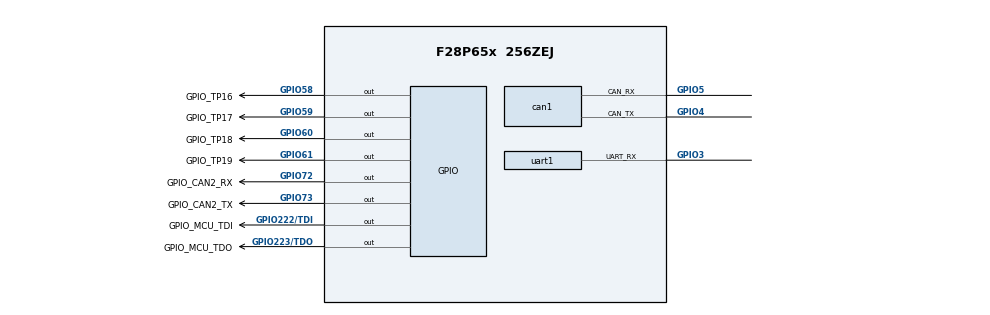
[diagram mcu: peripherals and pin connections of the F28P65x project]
/**
 * @cliArgs --device "F28P65x" --part "F28P65x_256ZEJ" --package "256ZEJ" --context "CPU1" --product "C2000WARE@6.00.01.00"
 * @versions {"tool":"1.26.0+4407"}
 */

/**
 * Import the modules used in this configuration.
 */
const adc       = scripting.addModule("/driverlib/adc.js", {}, false);
const adc1      = adc.addInstance();
const can       = scripting.addModule("/driverlib/can.js", {}, false);
const can1      = can.addInstance();
const gpio      = scripting.addModule("/driverlib/gpio.js", {}, false);
const gpio1     = gpio.addInstance();
const gpio2     = gpio.addInstance();
const gpio3     = gpio.addInstance();
const gpio4     = gpio.addInstance();
const gpio5     = gpio.addInstance();
const gpio6     = gpio.addInstance();
const gpio7     = gpio.addInstance();
const gpio8     = gpio.addInstance();
const uart      = scripting.addModule("/driverlib/uart.js", {}, false);
const uart1     = uart.addInstance();
const FREERTOS  = scripting.addModule("/kernel/freertos_tool/FREERTOS", {}, false);
const FREERTOS1 = FREERTOS.addInstance();

/**
 * Write custom configuration values to the imported modules.
 */
adc1.$name             = "myADC0";
adc1.adcClockPrescaler = "ADC_CLK_DIV_4_0";

const analog  = scripting.addModule("/driverlib/analog.js", {}, false);
const analog1 = analog.addInstance({}, false);
analog1.$name = "myANALOGPinMux0";
adc1.analog   = analog1;

can1.$name                 = "CAN1";
can1.can.can_rxPin.$assign = "GPIO5";
can1.can.can_txPin.$assign = "GPIO4";

gpio1.$name           = "GPIO_TP16";
gpio1.direction       = "GPIO_DIR_MODE_OUT";
gpio1.gpioPin.$assign = "GPIO58";

gpio2.$name           = "GPIO_TP17";
gpio2.direction       = "GPIO_DIR_MODE_OUT";
gpio2.gpioPin.$assign = "GPIO59";

gpio3.$name           = "GPIO_TP18";
gpio3.direction       = "GPIO_DIR_MODE_OUT";
gpio3.gpioPin.$assign = "GPIO60";

gpio4.$name           = "GPIO_TP19";
gpio4.direction       = "GPIO_DIR_MODE_OUT";
gpio4.gpioPin.$assign = "GPIO61";

gpio5.$name           = "GPIO_CAN2_RX";
gpio5.gpioPin.$assign = "GPIO72";

gpio6.$name           = "GPIO_CAN2_TX";
gpio6.direction       = "GPIO_DIR_MODE_OUT";
gpio6.gpioPin.$assign = "GPIO73";

gpio7.$name           = "GPIO_MCU_TDI";
gpio7.gpioPin.$assign = "GPIO222/TDI";

gpio8.$name           = "GPIO_MCU_TDO";
gpio8.direction       = "GPIO_DIR_MODE_OUT";
gpio8.gpioPin.$assign = "GPIO223/TDO";

uart1.$name                   = "UART";
uart1.uart.uart_rxPin.$assign = "GPIO3";
uart1.txQual.$name            = "myGPIOQUAL0";
uart1.rxQual.$name            = "myGPIOQUAL1";

FREERTOS1.$name = "myFREERTOS0";

/**
 * Pinmux solution for unlocked pins/peripherals. This ensures that minor changes to the automatic solver in a future
 * version of the tool will not impact the pinmux you originally saw.  These lines can be completely deleted in order to
 * re-solve from scratch.
 */
analog1.analog.$suggestSolution                    = "ANALOG";
analog1.analog["a0/daca_outPin"].$suggestSolution  = "A0/DACA_OUT";
analog1.analog.a1Pin.$suggestSolution              = "A1";
analog1.analog["a10, gpio213Pin"].$suggestSolution = "A10, GPIO213";
analog1.analog["a11, gpio214Pin"].$suggestSolution = "A11, GPIO214";
analog1.analog["a14/b14/c14Pin"].$suggestSolution  = "A14/B14/C14";
analog1.analog["a15/b15/c15Pin"].$suggestSolution  = "A15/B15/C15";
analog1.analog.a2Pin.$suggestSolution              = "A2";
analog1.analog.a3Pin.$suggestSolution              = "A3";
analog1.analog.a4Pin.$suggestSolution              = "A4";
analog1.analog.a5Pin.$suggestSolution              = "A5";
analog1.analog["a6, gpio209Pin"].$suggestSolution  = "A6, GPIO209";
analog1.analog["a7, gpio210Pin"].$suggestSolution  = "A7, GPIO210";
analog1.analog["a8, gpio211Pin"].$suggestSolution  = "A8, GPIO211";
analog1.analog["a9, gpio212Pin"].$suggestSolution  = "A9, GPIO212";
analog1.analog["b0/vdacPin"].$suggestSolution      = "B0/VDAC";
analog1.analog["b1/dacc_outPin"].$suggestSolution  = "B1/DACC_OUT";
analog1.analog["b10, gpio219Pin"].$suggestSolution = "B10, GPIO219";
analog1.analog.b11Pin.$suggestSolution             = "B11";
analog1.analog.b13Pin.$suggestSolution             = "B13";
analog1.analog.b2Pin.$suggestSolution              = "B2";
analog1.analog.b3Pin.$suggestSolution              = "B3";
analog1.analog["b4, gpio215Pin"].$suggestSolution  = "B4, GPIO215";
analog1.analog["b5, gpio216Pin"].$suggestSolution  = "B5, GPIO216";
analog1.analog["b6, gpio207Pin"].$suggestSolution  = "B6, GPIO207";
analog1.analog["b7, gpio208Pin"].$suggestSolution  = "B7, GPIO208";
analog1.analog["b8, gpio217Pin"].$suggestSolution  = "B8, GPIO217";
analog1.analog["b9, gpio218Pin"].$suggestSolution  = "B9, GPIO218";
analog1.analog["c0, gpio199Pin"].$suggestSolution  = "C0, GPIO199";
analog1.analog.c10Pin.$suggestSolution             = "C10";
analog1.analog.c11Pin.$suggestSolution             = "C11";
analog1.analog.c13Pin.$suggestSolution             = "C13";
analog1.analog.c2Pin.$suggestSolution              = "C2";
analog1.analog["c3, gpio206Pin"].$suggestSolution  = "C3, GPIO206";
analog1.analog["c4, gpio205Pin"].$suggestSolution  = "C4, GPIO205";
analog1.analog["c5, gpio204Pin"].$suggestSolution  = "C5, GPIO204";
analog1.analog["c6, gpio203Pin"].$suggestSolution  = "C6, GPIO203";
analog1.analog["c1, gpio200Pin"].$suggestSolution  = "C1, GPIO200";
analog1.analog["c7, gpio198Pin"].$suggestSolution  = "C7, GPIO198";
analog1.analog["c8, gpio202Pin"].$suggestSolution  = "C8, GPIO202";
analog1.analog["c9, gpio201Pin"].$suggestSolution  = "C9, GPIO201";
can1.can.$suggestSolution                          = "CANA";
uart1.uart.$suggestSolution                        = "UARTA";
uart1.uart.uart_txPin.$suggestSolution             = "GPIO2";
